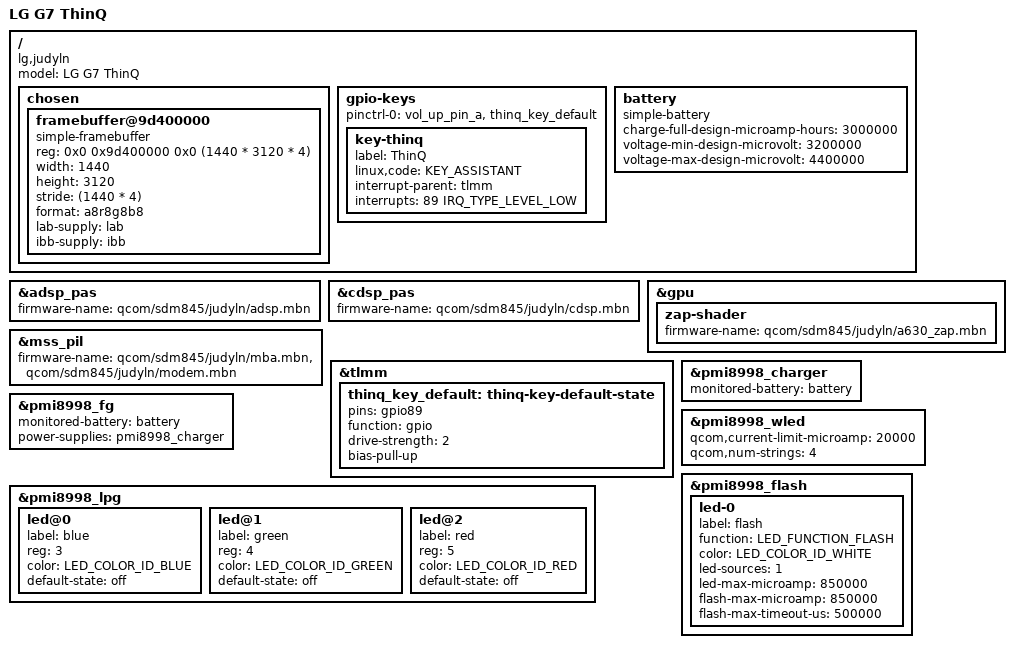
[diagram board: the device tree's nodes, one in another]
// SPDX-License-Identifier: GPL-2.0
/*
 * SDM845 LG G7 (judyln) device tree.
 *
 * Copyright (c) 2022, The Linux Foundation. All rights reserved.
 */

/dts-v1/;

#include "sdm845-lg-common.dtsi"
#include <dt-bindings/leds/common.h>

/ {
	model = "LG G7 ThinQ";
	compatible = "lg,judyln", "qcom,sdm845";

	chosen {
		framebuffer@9d400000 {
			compatible = "simple-framebuffer";
			reg = <0x0 0x9d400000 0x0 (1440 * 3120 * 4)>;
			width = <1440>;
			height = <3120>;
			stride = <(1440 * 4)>;
			format = "a8r8g8b8";
			lab-supply = <&lab>;
			ibb-supply = <&ibb>;
		};
	};

	/* Additional ThinQ key */
	gpio-keys {
		pinctrl-0 = <&vol_up_pin_a &thinq_key_default>;

		key-thinq {
			label = "ThinQ";
			linux,code = <KEY_ASSISTANT>;
			interrupt-parent = <&tlmm>;
			interrupts = <89 IRQ_TYPE_LEVEL_LOW>;
		};
	};

	battery: battery {
		status = "okay";
		compatible = "simple-battery";
		charge-full-design-microamp-hours = <3000000>;
		voltage-min-design-microvolt = <3200000>;
		voltage-max-design-microvolt = <4400000>;
	};

};

&adsp_pas {
	firmware-name = "qcom/sdm845/judyln/adsp.mbn";
};

&cdsp_pas {
	firmware-name = "qcom/sdm845/judyln/cdsp.mbn";
};

&gpu {
	zap-shader {
		firmware-name = "qcom/sdm845/judyln/a630_zap.mbn";
	};
};

&mss_pil {
	firmware-name = "qcom/sdm845/judyln/mba.mbn", "qcom/sdm845/judyln/modem.mbn";
};

&tlmm {
	thinq_key_default: thinq-key-default-state {
		pins = "gpio89";
		function = "gpio";
		drive-strength = <2>;
		bias-pull-up;
	};
};

&pmi8998_charger {
	status = "okay";
	monitored-battery = <&battery>;
};

&pmi8998_fg {
	status = "okay";
	monitored-battery = <&battery>;
	power-supplies = <&pmi8998_charger>;
};

&pmi8998_lpg {
	status = "okay";

	led@0 {
		label = "blue";
		reg = <3>;
		color = <LED_COLOR_ID_BLUE>;
		default-state = "off";
	};

	led@1 {
		label = "green";
		reg = <4>;
		color = <LED_COLOR_ID_GREEN>;
		default-state = "off";
	};

	led@2 {
		label = "red";
		reg = <5>;
		color = <LED_COLOR_ID_RED>;
		default-state = "off";
	};
};

&pmi8998_wled {
	status = "okay";
	qcom,current-limit-microamp = <20000>;
	qcom,num-strings = <4>;
};

&pmi8998_flash {
	status = "okay";

	led-0 {
		label = "flash";
		function = LED_FUNCTION_FLASH;
		color = <LED_COLOR_ID_WHITE>;
		led-sources = <1>;
		led-max-microamp = <850000>;
		flash-max-microamp = <850000>;
		flash-max-timeout-us = <500000>;
	};

};
